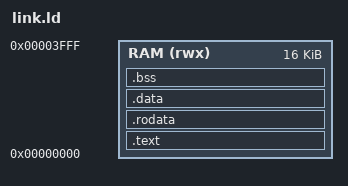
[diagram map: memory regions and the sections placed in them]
/* =============================================================================
 * link.ld - Toan bo chuong trinh nam trong RAM 16 KB bat dau tu 0x0000_0000
 * ========================================================================== */
OUTPUT_ARCH("riscv")
ENTRY(_start)

MEMORY
{
    RAM (rwx) : ORIGIN = 0x00000000, LENGTH = 16K
}

SECTIONS
{
    .text : {
        KEEP(*(.text.start))                      /* _start phai nam dau tien, tai dia chi 0 */
        *(.text .text.*)
    } > RAM

    .rodata : ALIGN(4) {
        *(.rodata .rodata.* .srodata .srodata.*)
    } > RAM

    .data : ALIGN(4) {
        *(.data .data.*)
        __global_pointer$ = . + 0x800;
        *(.sdata .sdata.*)
    } > RAM

    .bss (NOLOAD) : ALIGN(4) {
        __bss_start = .;
        *(.sbss .sbss.* .bss .bss.* COMMON)
        . = ALIGN(4);
        __bss_end = .;
    } > RAM

    __stack_top = ORIGIN(RAM) + LENGTH(RAM);
    /DISCARD/ : { *(.comment) *(.riscv.attributes) *(.note*) *(.eh_frame*) }
}
